VERSION ""

NS_ :

BS_:

BU_: XXX

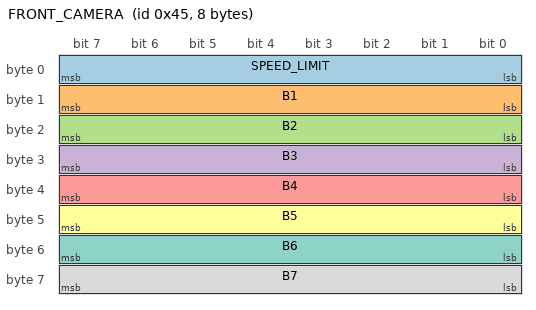
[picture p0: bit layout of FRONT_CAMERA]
BO_ 69 FRONT_CAMERA: 8 XXX
 SG_ SPEED_LIMIT : 0|8@1+ (1,0) [0|255] "kph" XXX
 SG_ B1 : 8|8@1+ (1,0) [0|255] "" XXX
 SG_ B2 : 16|8@1+ (1,0) [0|255] "" XXX
 SG_ B3 : 24|8@1+ (1,0) [0|255] "" XXX
 SG_ B4 : 32|8@1+ (1,0) [0|255] "" XXX
 SG_ B5 : 40|8@1+ (1,0) [0|255] "" XXX
 SG_ B6 : 48|8@1+ (1,0) [0|255] "" XXX
 SG_ B7 : 56|8@1+ (1,0) [0|255] "" XXX
